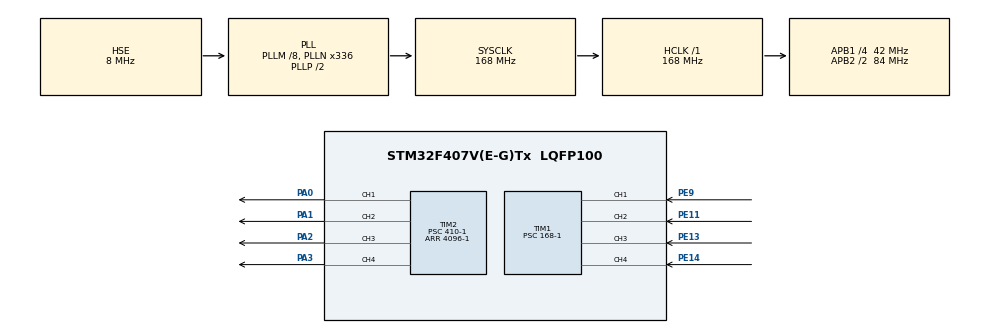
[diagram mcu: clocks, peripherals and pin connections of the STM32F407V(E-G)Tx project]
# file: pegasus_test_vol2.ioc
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Mcu.Family=STM32F4
Mcu.Name=STM32F407V(E-G)Tx
Mcu.Package=LQFP100
NVIC.PriorityGroup=NVIC_PRIORITYGROUP_0
NVIC.TIM1_CC_IRQn=true\:0\:0\:false\:false\:true\:true\:true\:true
PA0-WKUP.Signal=S_TIM2_CH1_ETR
PA1.Signal=S_TIM2_CH2
PA13.Mode=Serial_Wire
PA13.Signal=SYS_JTMS-SWDIO
PA14.Mode=Serial_Wire
PA14.Signal=SYS_JTCK-SWCLK
PA2.Signal=S_TIM2_CH3
PA3.Signal=S_TIM2_CH4
PE11.Signal=S_TIM1_CH2
PE13.Signal=S_TIM1_CH3
PE14.Signal=S_TIM1_CH4
PE9.Signal=S_TIM1_CH1
PH0-OSC_IN.Mode=HSE-External-Oscillator
PH0-OSC_IN.Signal=RCC_OSC_IN
PH1-OSC_OUT.Mode=HSE-External-Oscillator
PH1-OSC_OUT.Signal=RCC_OSC_OUT
ProjectManager.HeapSize=0x200
ProjectManager.StackSize=0x400
ProjectManager.TargetToolchain=STM32CubeIDE
RCC.48MHZClocksFreq_Value=48000000
RCC.AHBFreq_Value=168000000
RCC.APB1CLKDivider=RCC_HCLK_DIV4
RCC.APB1Freq_Value=42000000
RCC.APB1TimFreq_Value=84000000
RCC.APB2CLKDivider=RCC_HCLK_DIV2
RCC.APB2Freq_Value=84000000
RCC.APB2TimFreq_Value=168000000
RCC.CortexFreq_Value=168000000
RCC.HCLKFreq_Value=168000000
RCC.HSE_VALUE=8000000
RCC.HSI_VALUE=16000000
RCC.LSE_VALUE=32768
RCC.PLLM=8
RCC.PLLN=336
RCC.PLLQ=7
RCC.PLLSourceVirtual=RCC_PLLSOURCE_HSE
RCC.SYSCLKFreq_VALUE=168000000
RCC.SYSCLKSource=RCC_SYSCLKSOURCE_PLLCLK
RCC.VCOOutputFreq_Value=336000000
SH.S_TIM1_CH1.0=TIM1_CH1,Input_Capture1_from_TI1
SH.S_TIM1_CH2.0=TIM1_CH2,Input_Capture2_from_TI2
SH.S_TIM1_CH3.0=TIM1_CH3,Input_Capture3_from_TI3
SH.S_TIM1_CH4.0=TIM1_CH4,Input_Capture4_from_TI4
SH.S_TIM2_CH1_ETR.0=TIM2_CH1,PWM Generation1 CH1
SH.S_TIM2_CH2.0=TIM2_CH2,PWM Generation2 CH2
SH.S_TIM2_CH3.0=TIM2_CH3,PWM Generation3 CH3
SH.S_TIM2_CH4.0=TIM2_CH4,PWM Generation4 CH4
TIM1.Channel-Input_Capture1_from_TI1=TIM_CHANNEL_1
TIM1.Channel-Input_Capture2_from_TI2=TIM_CHANNEL_2
TIM1.Channel-Input_Capture3_from_TI3=TIM_CHANNEL_3
TIM1.Channel-Input_Capture4_from_TI4=TIM_CHANNEL_4
TIM1.Prescaler=168-1
TIM2.AutoReloadPreload=TIM_AUTORELOAD_PRELOAD_ENABLE
TIM2.Channel-PWM\ Generation1\ CH1=TIM_CHANNEL_1
TIM2.Channel-PWM\ Generation2\ CH2=TIM_CHANNEL_2
TIM2.Channel-PWM\ Generation3\ CH3=TIM_CHANNEL_3
TIM2.Channel-PWM\ Generation4\ CH4=TIM_CHANNEL_4
TIM2.Period=4096-1
TIM2.Prescaler=410-1
VP_TIM1_VS_ClockSourceINT.Mode=Internal
VP_TIM2_VS_ClockSourceINT.Mode=Internal
board=STM32F407G-DISC1

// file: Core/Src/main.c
/* USER CODE BEGIN Header */
/**
  ******************************************************************************
  * @file           : main.c
  * @brief          : Main program body
  ******************************************************************************
  * @attention
  *
  * Copyright (c) 2023 STMicroelectronics.
  * All rights reserved.
  *
  * This software is licensed under terms that can be found in the LICENSE file
  * in the root directory of this software component.
  * If no LICENSE file comes with this software, it is provided AS-IS.
  *
  ******************************************************************************
  */
/* USER CODE END Header */
#include "main.h"
#include <math.h>

TIM_HandleTypeDef htim1;
TIM_HandleTypeDef htim2;

void SystemClock_Config(void);
static void MX_GPIO_Init(void);
static void MX_TIM2_Init(void);
static void MX_TIM1_Init(void);
/* USER CODE BEGIN PFP */
float dutycycle=0;
/* USER CODE END PFP */
volatile uint32_t ch1_rising = 0, ch2_rising = 0, ch3_rising = 0, ch4_rising = 0;
volatile uint32_t ch1_falling = 0, ch2_falling = 0, ch3_falling = 0, ch4_falling = 0;
volatile uint32_t pre_ch1 = 0, ch1 = 0, pre_ch2 = 0, ch2 = 0, pre_ch3 = 0, ch3 = 0, pre_ch4 = 0, ch4 = 0;
void HAL_TIM_IC_CaptureCallback(TIM_HandleTypeDef *htim)
{
	if(htim->Instance == TIM1)  // interrupt TIM1 biriminden geliyorsa gir
	{
		switch(htim->Channel) // aktif kanal hamgisiyse, o kanalın case'ine git
		{
		case HAL_TIM_ACTIVE_CHANNEL_1:
			if((TIM1->CCER & TIM_CCER_CC1P)==0) // kanalin aktif olmasi kesmenin oradan gelecegi anlamina gelmez/gpio pinini kontrol et
			{
				ch1_rising = TIM1->CCR1; // yukselen kenar degerini kaydet
				TIM1->CCER |= TIM_CCER_CC1P; // polariteyi düsen kenar olarak degistir
			}

			else
			{
				ch1_falling = TIM1->CCR1;
				pre_ch1 = ch1_falling - ch1_rising; // dusen kenar degerini kaydet ve yukselen kenar degerinden cikar
				if(pre_ch1 < 0)pre_ch1 += 0xFFFF;// eger sonuc negatifse taban tumleme yap
				if(pre_ch1 < 2010 && pre_ch1 > 990)ch1=pre_ch1;
				TIM1->CCER &= ~TIM_CCER_CC1P; // polariteyi yukselen kenar olarak ayarla

				/*
				 * ch1_rising 65000
				 * ch1 falling 570
				 * pre_ch1 = pre_ch1 falling - pre_ch1_rising = 570 - 65000 = -64430
				 * pre_ch1 +=0xFFFF(65536) --> 1106
				 */
			}
			break;
		case HAL_TIM_ACTIVE_CHANNEL_2:
			if((TIM1->CCER & TIM_CCER_CC2P)==0)
			{
				ch2_rising = TIM1->CCR2;
				TIM1->CCER |= TIM_CCER_CC2P;
			}
			else
			{
				ch2_falling = TIM1->CCR2;
				pre_ch2 = ch2_falling - ch2_rising;
				if(pre_ch2 < 0)pre_ch2 += 0xFFFF;
				if(pre_ch2 < 2010 && pre_ch2 > 990)ch2=pre_ch2;
				TIM1->CCER &= ~TIM_CCER_CC2P;
			}
			break;
		case HAL_TIM_ACTIVE_CHANNEL_3:
			if((TIM1->CCER & TIM_CCER_CC3P)==0)
			{
				ch3_rising = TIM1->CCR3;
				TIM1->CCER |= TIM_CCER_CC3P;
			}
			else
			{
				ch3_falling = TIM1->CCR3;
				pre_ch3 = ch3_falling - ch3_rising;
				if(pre_ch3 < 0)pre_ch3 += 0xFFFF;
				if(pre_ch3 < 2010 && pre_ch3 > 990)ch3=pre_ch3;
				TIM1->CCER &= ~TIM_CCER_CC3P;
			}
			break;
		case HAL_TIM_ACTIVE_CHANNEL_4:
			if((TIM1->CCER & TIM_CCER_CC4P)==0)
			{
				ch4_rising = TIM1->CCR4;
				TIM1->CCER |= TIM_CCER_CC4P;
			}
			else
			{
				ch4_falling = TIM1->CCR4;
				pre_ch4 = ch4_falling - ch4_rising;
				if(pre_ch4 < 0)pre_ch4 += 0xFFFF;
				if(pre_ch4 < 2010 && pre_ch4 > 990)ch4=pre_ch4;
				TIM1->CCER &= ~TIM_CCER_CC4P;
			}
			break;
		default:
			break;
		}
	}
}

int main(void)
{

  /* MCU Configuration--------------------------------------------------------*/

  /* Reset of all peripherals, Initializes the Flash interface and the Systick. */
  HAL_Init();

  /* Configure the system clock */
  SystemClock_Config();

  /* Initialize all configured peripherals */
  MX_GPIO_Init();
  MX_TIM2_Init();
  MX_TIM1_Init();
  /* USER CODE BEGIN 2 */
  HAL_TIM_IC_Start_IT(&htim1, TIM_CHANNEL_1); // TIMX->DIER, CCXIE bitini aktif eder.
  HAL_TIM_IC_Start_IT(&htim1, TIM_CHANNEL_2);
  HAL_TIM_IC_Start_IT(&htim1, TIM_CHANNEL_3);
  HAL_TIM_IC_Start_IT(&htim1, TIM_CHANNEL_4);
  HAL_TIM_PWM_Start(&htim2, TIM_CHANNEL_1);
  HAL_TIM_PWM_Start(&htim2, TIM_CHANNEL_2);
  HAL_TIM_PWM_Start(&htim2, TIM_CHANNEL_3);
  HAL_TIM_PWM_Start(&htim2, TIM_CHANNEL_4);

  /* USER CODE END 2 */

  /* Infinite loop */
  /* USER CODE BEGIN WHILE */
  //TIM2->CCR1 = 420;
  //TIM2->CCR2 = 420;
  TIM2->CCR3 = 420;
  //TIM2->CCR4 = 420;
  HAL_Delay(3000);
  //TIM2->CCR1 = 220;
  //TIM2->CCR2 = 210;
  TIM2->CCR3 = 220;
  //TIM2->CCR4 = 220;
  HAL_Delay(3000);
  while (1)
  {
    /* USER CODE END WHILE */
	  dutycycle= (ch3/4.60);
	  if(dutycycle>420)
		  dutycycle=420;
	  //TIM2->CCR1 = dutycycle;
	  //TIM2->CCR2 = dutycycle;
	  TIM2->CCR3 = dutycycle;
	  //TIM2->CCR4 = dutycycle;
  }
}

void SystemClock_Config(void)
{
  RCC_OscInitTypeDef RCC_OscInitStruct = {0};
  RCC_ClkInitTypeDef RCC_ClkInitStruct = {0};

  /** Configure the main internal regulator output voltage
  */
  __HAL_RCC_PWR_CLK_ENABLE();
  __HAL_PWR_VOLTAGESCALING_CONFIG(PWR_REGULATOR_VOLTAGE_SCALE1);

  /** Initializes the RCC Oscillators according to the specified parameters
  * in the RCC_OscInitTypeDef structure.
  */
  RCC_OscInitStruct.OscillatorType = RCC_OSCILLATORTYPE_HSE;
  RCC_OscInitStruct.HSEState = RCC_HSE_ON;
  RCC_OscInitStruct.PLL.PLLState = RCC_PLL_ON;
  RCC_OscInitStruct.PLL.PLLSource = RCC_PLLSOURCE_HSE;
  RCC_OscInitStruct.PLL.PLLM = 8;
  RCC_OscInitStruct.PLL.PLLN = 336;
  RCC_OscInitStruct.PLL.PLLP = RCC_PLLP_DIV2;
  RCC_OscInitStruct.PLL.PLLQ = 7;
  if (HAL_RCC_OscConfig(&RCC_OscInitStruct) != HAL_OK)
  {
    Error_Handler();
  }

  /** Initializes the CPU, AHB and APB buses clocks
  */
  RCC_ClkInitStruct.ClockType = RCC_CLOCKTYPE_HCLK|RCC_CLOCKTYPE_SYSCLK
                              |RCC_CLOCKTYPE_PCLK1|RCC_CLOCKTYPE_PCLK2;
  RCC_ClkInitStruct.SYSCLKSource = RCC_SYSCLKSOURCE_PLLCLK;
  RCC_ClkInitStruct.AHBCLKDivider = RCC_SYSCLK_DIV1;
  RCC_ClkInitStruct.APB1CLKDivider = RCC_HCLK_DIV4;
  RCC_ClkInitStruct.APB2CLKDivider = RCC_HCLK_DIV2;

  if (HAL_RCC_ClockConfig(&RCC_ClkInitStruct, FLASH_LATENCY_5) != HAL_OK)
  {
    Error_Handler();
  }
}

static void MX_TIM1_Init(void)
{

  TIM_ClockConfigTypeDef sClockSourceConfig = {0};
  TIM_MasterConfigTypeDef sMasterConfig = {0};
  TIM_IC_InitTypeDef sConfigIC = {0};

  htim1.Instance = TIM1;
  htim1.Init.Prescaler = 168-1;
  htim1.Init.CounterMode = TIM_COUNTERMODE_UP;
  htim1.Init.Period = 65535;
  htim1.Init.ClockDivision = TIM_CLOCKDIVISION_DIV1;
  htim1.Init.RepetitionCounter = 0;
  htim1.Init.AutoReloadPreload = TIM_AUTORELOAD_PRELOAD_DISABLE;
  if (HAL_TIM_Base_Init(&htim1) != HAL_OK)
  {
    Error_Handler();
  }
  sClockSourceConfig.ClockSource = TIM_CLOCKSOURCE_INTERNAL;
  if (HAL_TIM_ConfigClockSource(&htim1, &sClockSourceConfig) != HAL_OK)
  {
    Error_Handler();
  }
  if (HAL_TIM_IC_Init(&htim1) != HAL_OK)
  {
    Error_Handler();
  }
  sMasterConfig.MasterOutputTrigger = TIM_TRGO_RESET;
  sMasterConfig.MasterSlaveMode = TIM_MASTERSLAVEMODE_DISABLE;
  if (HAL_TIMEx_MasterConfigSynchronization(&htim1, &sMasterConfig) != HAL_OK)
  {
    Error_Handler();
  }
  sConfigIC.ICPolarity = TIM_INPUTCHANNELPOLARITY_RISING;
  sConfigIC.ICSelection = TIM_ICSELECTION_DIRECTTI;
  sConfigIC.ICPrescaler = TIM_ICPSC_DIV1;
  sConfigIC.ICFilter = 0;
  if (HAL_TIM_IC_ConfigChannel(&htim1, &sConfigIC, TIM_CHANNEL_1) != HAL_OK)
  {
    Error_Handler();
  }
  if (HAL_TIM_IC_ConfigChannel(&htim1, &sConfigIC, TIM_CHANNEL_2) != HAL_OK)
  {
    Error_Handler();
  }
  if (HAL_TIM_IC_ConfigChannel(&htim1, &sConfigIC, TIM_CHANNEL_3) != HAL_OK)
  {
    Error_Handler();
  }
  if (HAL_TIM_IC_ConfigChannel(&htim1, &sConfigIC, TIM_CHANNEL_4) != HAL_OK)
  {
    Error_Handler();
  }

}

static void MX_TIM2_Init(void)
{

  TIM_ClockConfigTypeDef sClockSourceConfig = {0};
  TIM_MasterConfigTypeDef sMasterConfig = {0};
  TIM_OC_InitTypeDef sConfigOC = {0};

  htim2.Instance = TIM2;
  htim2.Init.Prescaler = 410-1;
  htim2.Init.CounterMode = TIM_COUNTERMODE_UP;
  htim2.Init.Period = 4096-1;
  htim2.Init.ClockDivision = TIM_CLOCKDIVISION_DIV1;
  htim2.Init.AutoReloadPreload = TIM_AUTORELOAD_PRELOAD_ENABLE;
  if (HAL_TIM_Base_Init(&htim2) != HAL_OK)
  {
    Error_Handler();
  }
  sClockSourceConfig.ClockSource = TIM_CLOCKSOURCE_INTERNAL;
  if (HAL_TIM_ConfigClockSource(&htim2, &sClockSourceConfig) != HAL_OK)
  {
    Error_Handler();
  }
  if (HAL_TIM_PWM_Init(&htim2) != HAL_OK)
  {
    Error_Handler();
  }
  sMasterConfig.MasterOutputTrigger = TIM_TRGO_RESET;
  sMasterConfig.MasterSlaveMode = TIM_MASTERSLAVEMODE_DISABLE;
  if (HAL_TIMEx_MasterConfigSynchronization(&htim2, &sMasterConfig) != HAL_OK)
  {
    Error_Handler();
  }
  sConfigOC.OCMode = TIM_OCMODE_PWM1;
  sConfigOC.Pulse = 0;
  sConfigOC.OCPolarity = TIM_OCPOLARITY_HIGH;
  sConfigOC.OCFastMode = TIM_OCFAST_DISABLE;
  if (HAL_TIM_PWM_ConfigChannel(&htim2, &sConfigOC, TIM_CHANNEL_1) != HAL_OK)
  {
    Error_Handler();
  }
  if (HAL_TIM_PWM_ConfigChannel(&htim2, &sConfigOC, TIM_CHANNEL_2) != HAL_OK)
  {
    Error_Handler();
  }
  if (HAL_TIM_PWM_ConfigChannel(&htim2, &sConfigOC, TIM_CHANNEL_3) != HAL_OK)
  {
    Error_Handler();
  }
  if (HAL_TIM_PWM_ConfigChannel(&htim2, &sConfigOC, TIM_CHANNEL_4) != HAL_OK)
  {
    Error_Handler();
  }
  HAL_TIM_MspPostInit(&htim2);

}

static void MX_GPIO_Init(void)
{

  /* GPIO Ports Clock Enable */
  __HAL_RCC_GPIOH_CLK_ENABLE();
  __HAL_RCC_GPIOA_CLK_ENABLE();
  __HAL_RCC_GPIOE_CLK_ENABLE();

}

void Error_Handler(void)
{
  __disable_irq();
  while (1)
  {
  }
}
